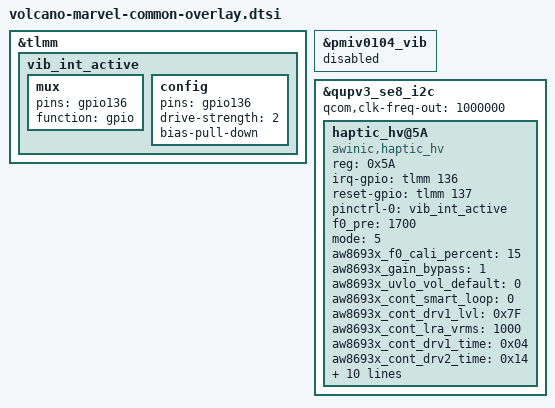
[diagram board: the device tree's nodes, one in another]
/* Copyright (c) 2021, The Linux Foundation. All rights reserved.
 *
 * This program is free software; you can redistribute it and/or modify
 * it under the terms of the GNU General Public License version 2 and
 * only version 2 as published by the Free Software Foundation.
 *
 * This program is distributed in the hope that it will be useful,
 * but WITHOUT ANY WARRANTY; without even the implied warranty of
 * MERCHANTABILITY or FITNESS FOR A PARTICULAR PURPOSE.  See the
 * GNU General Public License for more details.
 */
#include "volcano-moto-common-overlay.dtsi"
#include "volcano-moto-common-overlay-base.dtsi"
#include "volcano-marvel-charger-overlay.dtsi"
#include "volcano-marvel-sensor-overlay.dtsi"
#include "volcano-marvel-thermal-overlay.dtsi"
#include "volcano-marvel-nfc-overlay.dtsi"
#include "volcano-marvel-fps-overlay.dtsi"
#include "moto-marvel-aw37004.dtsi"
#include "volcano-marvel-touchscreen-overlay.dtsi"
#include "volcano-marvel-wlan-antenna-control.dtsi"

&tlmm {
	vib_int_active: vib_int_active {
		/* active state */
		mux {
			pins = "gpio136";
			function = "gpio";
		};
		config {
			pins = "gpio136";
			drive-strength = <2>; /* 2 MA */
			bias-pull-down;
		};
	};

};

&pmiv0104_vib {
	status = "disabled";
};

&qupv3_se8_i2c {
	status = "ok";
	qcom,clk-freq-out = <1000000>;
	#address-cells = <1>;
	#size-cells = <0>;
	haptic_hv@5A {
		status = "okay";
		compatible = "awinic,haptic_hv";
		reg = <0x5A>;
		irq-gpio = <&tlmm 136 0>;
		reset-gpio = <&tlmm 137 0>;
		pinctrl-names = "irq_active";
		pinctrl-0 = <&vib_int_active>;
		f0_pre = < 1700 >;
		mode = /bits/ 8 < 5 >;

		aw8693x_f0_cali_percent = /bits/ 8 < 15 >;
		aw8693x_gain_bypass = /bits/ 8 < 1 >;
		aw8693x_uvlo_vol_default = /bits/ 8 < 0 >;
		aw8693x_cont_smart_loop = /bits/ 8 < 0 >;
		aw8693x_cont_drv1_lvl = /bits/ 8 < 0x7F >;
		aw8693x_cont_lra_vrms = < 1000 >;
		aw8693x_cont_drv1_time = /bits/ 8 < 0x04 >;
		aw8693x_cont_drv2_time = /bits/ 8 < 0x14 >;
		aw8693x_cont_track_margin = /bits/ 8 < 0x0F >;
		aw8693x_cont_brk_gain = /bits/ 8 < 0x08 >;
		aw8693x_cont_brk_time = /bits/ 8 < 0x08 >;
		aw8693x_duration_time = /bits/ 8 < 20 30 60 >;
		aw8693x_d2s_gain = /bits/ 8 < 0x04 >;
		aw8693x_trig_config = /bits/ 8 < 0 0 0 1 0 2 0 0
						 0 0 0 1 0 2 0 0
						 0 0 0 1 0 2 0 0 >;
		aw8693x_bst_vol_default = < 8500 >;
		aw8693x_is_pwm_12k;
		aw8693x_is_enabled_track_en;
	};
};
